# M3 register map
File version: 1.2
Registers are 32-bit, read-write, reset 0x0 unless marked. A register's access mark holds for its fields unless they carry their own. Offsets are from the block's base; lines under a group give offsets from that group; [hi:lo] are bit positions; {n}, {i} and the like mark numbered series; 'fields as' and 'values as' point back to an identical list; <NAME> marks a mode.

## Memory map
0xE000E000 NVIC size 0x1001 — Nested Vectored Interrupt Controller
0xE000E010 SysTick size 0x1000
0xE000ED10 SCB size 0x1000
0xE000ED28 Fault_Reports size 0x1000

## Interrupts
15 SysTick

## NVIC — Nested Vectored Interrupt Controller
Base 0xE000E000
0x04 ICTR ro — Interrupt Controller Type Register
  [3:0] INTLINESNUM — Total number of interrupt lines in groups
{0x100+4i} ISER{i} (i=0..2) — Interrupt Set-Enable Register
  [31:0] SETENA
{0x180+4i} ICER{i} (i=0..2) — Interrupt Clear-Enable Register
  [31:0] CLRENA
{0x200+4i} ISPR{i} (i=0..2) — Interrupt Set-Pending Register
  [31:0] SETPEND
{0x280+4i} ICPR{i} (i=0..2) — Interrupt Clear-Pending Register
  [31:0] CLRPEND
{0x300+4i} IABR{i} ro (i=0..2) — Interrupt Active Bit Register
  [31:0] ACTIVE
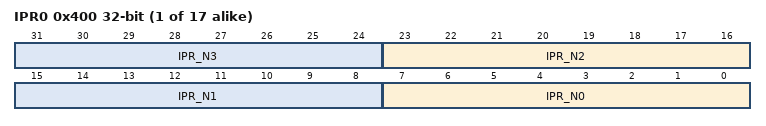
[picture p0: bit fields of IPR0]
{0x400+4i} IPR{i} (i=0..16) — Interrupt Priority Register
  [8n+7:8n] IPR_N{n} (n=0..3)
0xF00 STIR wo — Software Triggered Interrupt Register
  [8:0] INTID — interrupt to be triggered

## SCB
Base 0xE000ED10
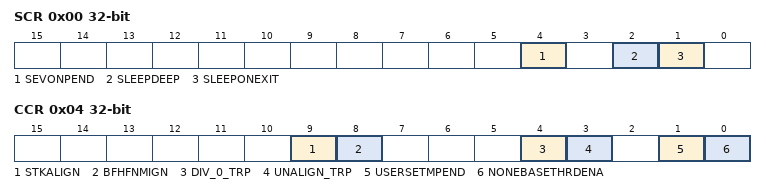
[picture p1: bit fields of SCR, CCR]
0x00 SCR
  [4] SEVONPEND, [2] SLEEPDEEP, [1] SLEEPONEXIT
0x04 CCR
  [9] STKALIGN, [8] BFHFNMIGN, [4] DIV_0_TRP, [3] UNALIGN_TRP, [1] USERSETMPEND, [0] NONEBASETHRDENA

## SysTick
Base 0xE000E010
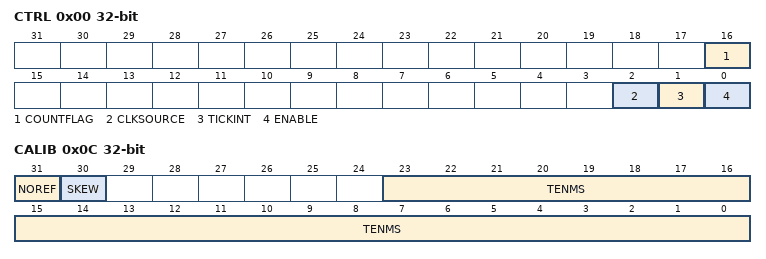
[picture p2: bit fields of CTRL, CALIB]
0x00 CTRL
  [16] COUNTFLAG, [2] CLKSOURCE, [1] TICKINT, [0] ENABLE
0x04 LOAD
  [23:0] RELOAD
0x08 VAL
  [23:0] CURRENT
0x0C CALIB
  [31] NOREF, [30] SKEW, [23:0] TENMS

## Fault_Reports
Base 0xE000ED28
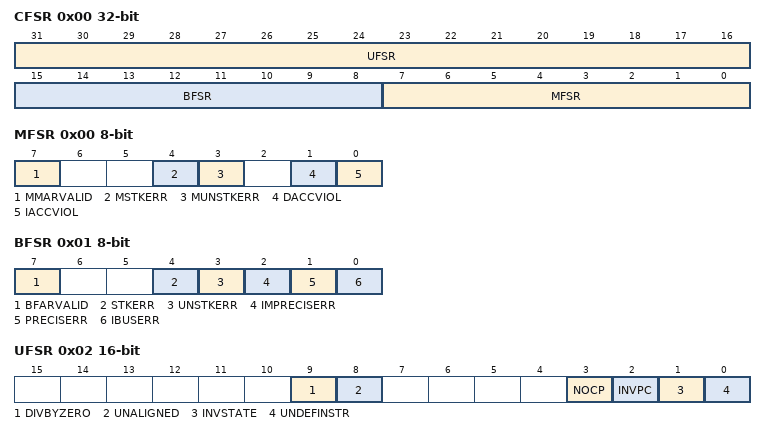
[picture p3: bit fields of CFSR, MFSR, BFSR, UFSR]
0x00 CFSR
  [31:16] UFSR, [15:8] BFSR, [7:0] MFSR
0x00 MFSR 8-bit (Fault_Reports view)
  [7] MMARVALID, [4] MSTKERR, [3] MUNSTKERR, [1] DACCVIOL, [0] IACCVIOL
0x01 BFSR 8-bit
  [7] BFARVALID, [4] STKERR, [3] UNSTKERR, [2] IMPRECISERR, [1] PRECISERR, [0] IBUSERR
0x02 UFSR 16-bit
  [9] DIVBYZERO, [8] UNALIGNED, [3] NOCP, [2] INVPC, [1] INVSTATE, [0] UNDEFINSTR
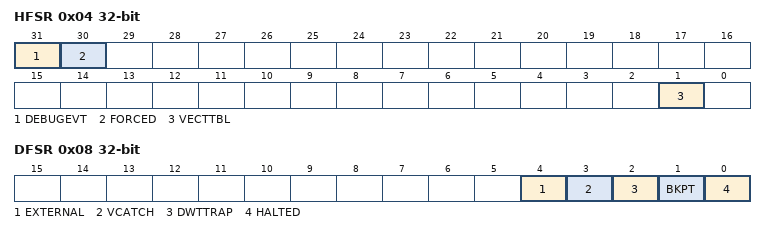
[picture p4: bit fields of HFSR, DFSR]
0x04 HFSR
  [31] DEBUGEVT, [30] FORCED, [1] VECTTBL
0x08 DFSR
  [4] EXTERNAL, [3] VCATCH, [2] DWTTRAP, [1] BKPT, [0] HALTED
0x0C MMFAR
  [31:0] ADDRESS
0x10 BFAR
  [31:0] ADDRESS
0x14 AFSR
  [31:0] IMPDEF
